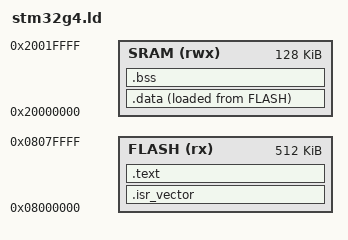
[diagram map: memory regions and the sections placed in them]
MEMORY
{
    FLASH (rx)  : ORIGIN = 0x08000000, LENGTH = 512K
    SRAM  (rwx) : ORIGIN = 0x20000000, LENGTH = 128K
}

SECTIONS
{
    .isr_vector :
    {
        KEEP(*(.isr_vector))
    } > FLASH

    .text :
    {
        *(.text*)
        *(.rodata*)
    } > FLASH

    .data :
    {
        _sdata = .;
        *(.data*)
        _edata = .;
    } > SRAM AT > FLASH

    .bss :
    {
        _sbss = .;
        *(.bss*)
        *(COMMON)
        _ebss = .;
    } > SRAM

    /DISCARD/ : { *(.eh_frame) }
}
